# STM32H5E5xx register map
File version: 1.0
Registers are 32-bit, read-write, reset 0x0 unless marked. A register's access mark holds for its fields unless they carry their own. Offsets are from the block's base; [hi:lo] are bit positions; {n}, {i} and the like mark numbered series.

## SBS — System configuration, Boot and Security
Base 0x44000400
Same registers: SBS_S 0x54000400
0x10 HDPLCR — SBS HDPL Control Register
  [7:0] INCR_HDPL — Increment HDPL value
0x14 HDPLSR — SBS HDPL Status Register
  [7:0] HDPL — HDPL value
0x18 NEXTHDPLCR — NEXT HDPL Control Register
  [1:0] NEXTHDPL — NEXTHDPL value
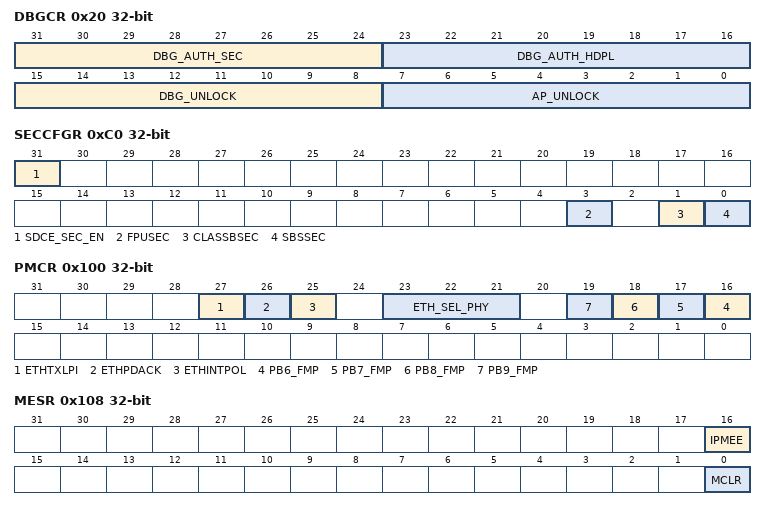
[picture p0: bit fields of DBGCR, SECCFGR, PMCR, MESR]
0x20 DBGCR — SBS Debug Control Register
  [31:24] DBG_AUTH_SEC — Open the non-secured and secured debugs
  [23:16] DBG_AUTH_HDPL — HDPL value when the debug should be effectively opened
  [15:8] DBG_UNLOCK — Open the debug when DBG_AUTH_HDPL is reached
  [7:0] AP_UNLOCK — Open the Access Port
0x24 DBGLOCKR — SBS Debug Lock Register
  [7:0] DBGCFG_LOCK — SBS_DBGLOCKR_DBGCFG_LOCK value
0x34 RSSCMDR — SBS RSS Command Register
  [15:0] RSSCMD — command to be executed by the RSS
0xA0 EPOCHSELCR — EPOCH Selection Register
  [1:0] EPOCH_SEL — Select EPOCH sent to SAES IP to encrypt/decrypt keys
0xC0 SECCFGR — SBS Security Mode Configuration
  [31] SDCE_SEC_EN — SMPS SBS security enable
  [3] FPUSEC — FPU SBS security enable
  [1] CLASSBSEC — ClassB SBS security enable
  [0] SBSSEC — SBS clock control security enable
0x100 PMCR — SBS Product Mode & Config Register
  [27] ETHTXLPI — ETH TxLPI status
  [26] ETHPDACK — ETH power-down acknowledge
  [25] ETHINTPOL — ETH external PHY interrupt polarity configuration
  [23:21] ETH_SEL_PHY — Ethernet PHY Interface Selection
    0=MII (Select the Media Independent Interface (MII) or GMII); 4=RMII (Select the Reduced Media Independent Interface (RMII))
  [n+10] PB{n}_FMP (n=6..9) — Fast-mode Plus command on PB({n})
0x104 FPUIMR — SBS FPU Interrupt Mask Register
  [5:0] FPU_IE — All FPU interrupts enable
0x108 MESR — SBS Memory Erase Status Register
  [16] IPMEE — Status of End of Erase for ICache and PKA RAMs
  [0] MCLR — Status of Erase after Reset
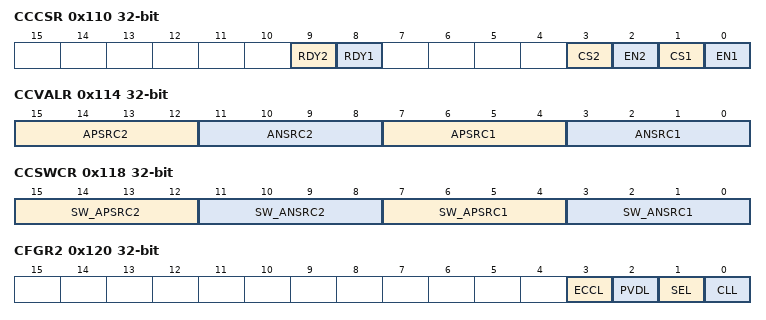
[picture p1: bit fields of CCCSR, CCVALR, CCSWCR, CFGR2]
0x110 CCCSR — SBS Compensation Cell Control & Status Register
  [9] RDY2 — VDDIO compensation cell ready flag
  [8] RDY1 — VDD compensation cell ready flag
  [3] CS2 — Code selection for VDDIO power rail
  [2] EN2 — Enable compensation cell for VDDIO power rail
  [1] CS1 — Code selection for VDD power rail
  [0] EN1 — Enable compensation cell for VDD power rail
0x114 CCVALR — SBS Compensation Cell Value Register
  [15:12] APSRC2 — PMOS compensation value
  [11:8] ANSRC2 — NMOS compensation value
  [7:4] APSRC1 — PMOS compensation value
  [3:0] ANSRC1 — NMOS compensation value
0x118 CCSWCR — SBS Compensation Cell for I/Os sw code Register
  [15:12] SW_APSRC2 — PMOS compensation code for VDDIO Power Rail
  [11:8] SW_ANSRC2 — NMOS compensation code for VDDIO Power Rail
  [7:4] SW_APSRC1 — PMOS compensation code for VDD Power Rail
  [3:0] SW_ANSRC1 — NMOS compensation code for VDD Power Rail
0x120 CFGR2 — SBS Class B Register
  [3] ECCL — Flash ECC Lock
  [2] PVDL — PVD Lock
  [1] SEL — SRAM ECC Lock
  [0] CLL — Core Lockup Lock
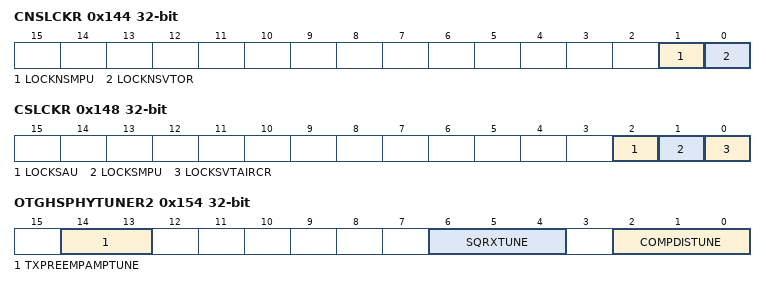
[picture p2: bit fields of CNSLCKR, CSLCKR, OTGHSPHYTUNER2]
0x144 CNSLCKR — SBS CPU Non-secure Lock Register
  [1] LOCKNSMPU — Disable Non-Secure MPU registers writes by SW or debug agent
  [0] LOCKNSVTOR — Disable VTOR_NS register writes by SW or debug agent
0x148 CSLCKR — SBS CPU Secure Lock Register
  [2] LOCKSAU — Disable changes to SAU registers
  [1] LOCKSMPU — Disable changes to the secure MPU registers writes by SW or debug agent
  [0] LOCKSVTAIRCR — Disable changes to the secure vector table address, handling of system faults
0x14C ECCNMIR — SBS FLITF ECC NMI MASK Register
  [0] ECCNMI_MASK_EN — Disable NMI in case of double ECC error in flash interface
0x154 OTGHSPHYTUNER2 — SBS OTG_HS PHY tune register 2
  [14:13] TXPREEMPAMPTUNE — Disconnect threshold adjustment
    0=DISABLED (HS transmitter preemphasis circuit disabled); 1=PREEMP_1X (HS transmitter preemphasis circuit sources 1x preemphasis current); 2=PREEMP_2X (HS transmitter preemphasis circuit sources 2x preemphasis current); 3=PREEMP_3X
  [6:4] SQRXTUNE — Squelch threshold adjustment
    0=SQUELCH_15PERCENT (+15% (recommended value)); 3=SQUELCH_0PERCENT (0% (default value))
  [2:0] COMPDISTUNE — High-speed (HS) transmitter preemphasis current control
    2=DISCONNECT_5_9PERCENT (+5.9% (recommended value)); 1=DISCONNECT_0PERCENT (0% (default value))
